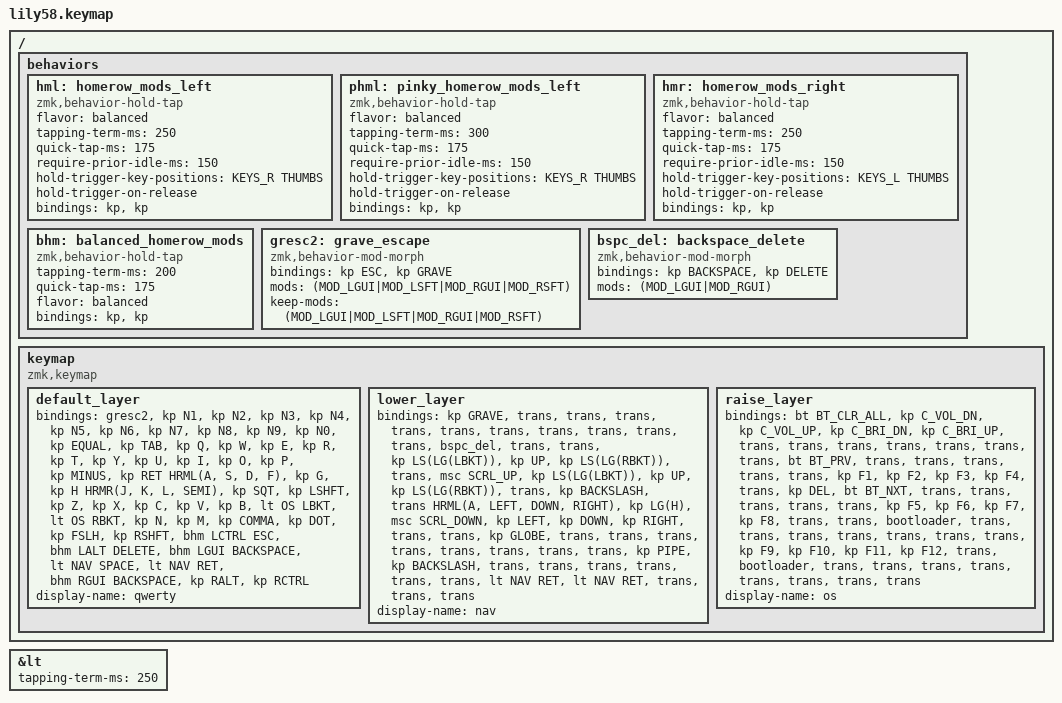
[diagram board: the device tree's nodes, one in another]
/*
 * Copyright (c) 2020 The ZMK Contributors
 *
 * SPDX-License-Identifier: MIT
 */

#include <behaviors.dtsi>
#include <dt-bindings/zmk/keys.h>
#include <dt-bindings/zmk/bt.h>
#include <dt-bindings/zmk/ext_power.h>

#define ZMK_POINTING_DEFAULT_SCRL_VAL 25    // default: 10

#include <dt-bindings/zmk/pointing.h>

#define HRML(k1,k2,k3,k4) &phml LCTRL k1 &hml LALT k2 &hml LGUI k3 &hml LSHIFT k4
#define HRMR(k1,k2,k3,k4) &hmr RSHFT k1 &hmr RGUI k2 &hmr RALT k3 &hmr RCTRL k4

// Lily58 key positions, used so a home-row mod only turns into a mod
// when the next key is on the other hand (or a thumb key)
#define KEYS_L 0 1 2 3 4 5 12 13 14 15 16 17 24 25 26 27 28 29 36 37 38 39 40 41 42
#define KEYS_R 6 7 8 9 10 11 18 19 20 21 22 23 30 31 32 33 34 35 43 44 45 46 47 48 49
#define THUMBS 50 51 52 53 54 55 56 57

#define QWERTY 0
#define NAV   1
#define OS   2

&lt {
    tapping-term-ms = <250>;
};

/ {
    behaviors {
        // Left home row (S, D, F)
        hml: homerow_mods_left {
            compatible = "zmk,behavior-hold-tap";
            #binding-cells = <2>;
            flavor = "balanced";
            tapping-term-ms = <250>;
            quick-tap-ms = <175>;                // tap then hold = repeat the letter
            require-prior-idle-ms = <150>;       // typing fast = always a letter
            hold-trigger-key-positions = <KEYS_R THUMBS>;  // mod only with other hand
            hold-trigger-on-release;             // allows stacking mods on one hand
            bindings = <&kp>, <&kp>;
        };

        // Left pinky (A): a bit more time, pinkies are slower
        phml: pinky_homerow_mods_left {
            compatible = "zmk,behavior-hold-tap";
            #binding-cells = <2>;
            flavor = "balanced";
            tapping-term-ms = <300>;
            quick-tap-ms = <175>;                // tap then hold = repeat the letter
            require-prior-idle-ms = <150>;       // typing fast = always a letter
            hold-trigger-key-positions = <KEYS_R THUMBS>;  // mod only with other hand
            hold-trigger-on-release;             // allows stacking mods on one hand
            bindings = <&kp>, <&kp>;
        };

        // Right home row (J, K, L, ;)
        hmr: homerow_mods_right {
            compatible = "zmk,behavior-hold-tap";
            #binding-cells = <2>;
            flavor = "balanced";
            tapping-term-ms = <250>;
            quick-tap-ms = <175>;                // tap then hold = repeat the letter
            require-prior-idle-ms = <150>;       // typing fast = always a letter
            hold-trigger-key-positions = <KEYS_L THUMBS>;  // mod only with other hand
            hold-trigger-on-release;             // allows stacking mods on one hand
            bindings = <&kp>, <&kp>;
        };

        bhm: balanced_homerow_mods {
            compatible = "zmk,behavior-hold-tap";
            #binding-cells = <2>;
            tapping-term-ms = <200>;    // <---[[moderate duration]]
            quick-tap-ms = <175>;       // tap then hold = repeat (e.g. backspace)
            flavor = "balanced";
            bindings = <&kp>, <&kp>;
        };

        gresc2: grave_escape {
            compatible = "zmk,behavior-mod-morph";
            #binding-cells = <0>;
            bindings = <&kp ESC>, <&kp GRAVE>;
            mods = <(MOD_LGUI|MOD_LSFT|MOD_RGUI|MOD_RSFT)>;
            keep-mods = <(MOD_LGUI|MOD_LSFT|MOD_RGUI|MOD_RSFT)>;
        };

        bspc_del: backspace_delete {
            compatible = "zmk,behavior-mod-morph";
            #binding-cells = <0>;
            bindings = <&kp BACKSPACE>, <&kp DELETE>;
            mods = <(MOD_LGUI|MOD_RGUI)>;
        };
    };

    keymap {
        compatible = "zmk,keymap";

        default_layer {
// ------------------------------------------------------------------------------------------------------------
// |  ESC  |  1  |  2  |  3   |  4   |  5   |                   |  6   |  7    |  8    |  9   |   0   |   `   |
// |  TAB  |  Q  |  W  |  E   |  R   |  T   |                   |  Y   |  U    |  I    |  O   |   P   |   -   |
// |  CTRL |  A  |  S  |  D   |  F   |  G   |                   |  H   |  J    |  K    |  L   |   ;   |   '   |
// | SHIFT |  Z  |  X  |  C   |  V   |  B   |   "["  |  |  "]"  |  N   |  M    |  ,    |  .   |   /   | SHIFT |
//                     | ALT  | GUI  | LOWER|  SPACE |  | ENTER | RAISE| BSPC  | GUI   |
            bindings = <
&gresc2      &kp N1 &kp N2 &kp N3   &kp N4   &kp N5                         &kp N6 &kp N7   &kp N8    &kp N9  &kp N0   &kp EQUAL
&kp TAB      &kp Q  &kp W  &kp E    &kp R    &kp T                          &kp Y  &kp U    &kp I     &kp O   &kp P    &kp MINUS
&kp RET      HRML(A, S, D, F)    &kp G                           &kp H  HRMR(J, K, L, SEMI)  &kp SQT
&kp LSHFT    &kp Z  &kp X  &kp C    &kp V    &kp B  &lt OS LBKT   &lt OS RBKT &kp N  &kp M  &kp COMMA &kp DOT &kp FSLH &kp RSHFT
             &bhm LCTRL ESC  &bhm LALT DELETE &bhm LGUI BACKSPACE  &lt NAV SPACE   &lt NAV RET    &bhm RGUI BACKSPACE  &kp RALT  &kp RCTRL
            >;

            display-name = "qwerty";
        };

        lower_layer {
// ------------------------------------------------------------------------------------------------------------
// | BTCLR | BT1 | BT2 |  BT3 |  BT4 |  BT5 |                   |      |       |       |      |       |       |
// |  F1   |  F2 |  F3 |  F4  |  F5  |  F6  |                   |  F7  |  F8   |  F9   |  F10 |  F11  |  F12  |
// |   `   |  !  |  @  |  #   |  $   |  %   |                   |  ^   |  &    |  *    |  (   |   )   |   ~   |
// |       |     |     |      |      |      |        |  |       |      |  _    |  +    |  {   |   }   |  "|"  |
//                     |      |      |      |        |  |       |      |       |       |
            bindings = <
&kp GRAVE  &trans  &trans  &trans   &trans  &trans                     &trans  &trans   &trans  &trans  &trans  &bspc_del
&trans      &trans  &kp LS(LG(LBKT))  &kp UP  &kp LS(LG(RBKT))  &trans                   &msc SCRL_UP  &kp LS(LG(LBKT))  &kp UP  &kp LS(LG(RBKT))  &trans &kp BACKSLASH     
&trans      HRML(A, LEFT, DOWN, RIGHT)  &kp LG(H)                      &msc SCRL_DOWN  &kp LEFT  &kp DOWN  &kp RIGHT &trans  &trans
&kp GLOBE      &trans  &trans  &trans  &trans &trans   &trans  &trans  &trans  &kp PIPE  &kp BACKSLASH  &trans  &trans  &trans
                            &trans  &trans &trans   &lt NAV RET  &lt NAV RET  &trans  &trans  &trans
            >;

            display-name = "nav";
        };

        raise_layer {
// ------------------------------------------------------------------------------------------------------------
// |       |     |     |      |      |      |                   |      |       |       |      |       |       |
// |   `   |  1  |  2  |  3   |  4   |  5   |                   |  6   |   7   |   8   |  9   |   0   |       |
// |   F1  |  F2 |  F3 |  F4  |  F5  |  F6  |                   |      |   <-  |   v   |  ^   |  ->   |       |
// |   F7  |  F8 |  F9 |  F10 |  F11 |  F12 |        |  |       |  +   |   -   |   =   |  [   |   ]   |   \   |
//                     |      |      |      |        |  |       |      |       |       |
            bindings = <
&bt BT_CLR_ALL      &kp C_VOL_DN  &kp C_VOL_UP  &kp C_BRI_DN  &kp C_BRI_UP &trans                   &trans  &trans  &trans  &trans  &trans  &trans
&bt BT_PRV   &trans  &trans  &trans  &trans &trans                   &kp F1    &kp F2 &kp F3 &kp F4  &trans  &kp DEL
&bt BT_NXT   &trans  &trans  &trans  &trans &trans                   &kp F5  &kp F6   &kp F7    &kp F8  &trans &trans
&bootloader &trans  &trans  &trans  &trans &trans   &trans  &trans  &kp F9 &kp F10 &kp F11   &kp F12  &trans  &bootloader
                            &trans  &trans  &trans   &trans  &trans  &trans  &trans  &trans
            >;

            display-name = "os";
        };
    };
};
